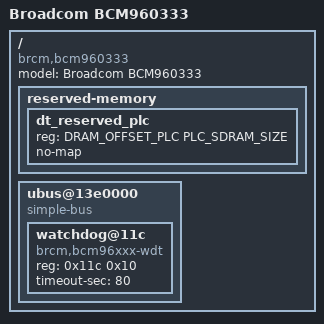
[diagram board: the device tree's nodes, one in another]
/*
 * Broadcom BCM63138 Reference Board DTS
 */

#include "bcm_963xx_template.dtsi"

/ {
    compatible = "brcm,bcm960333";
    model = "Broadcom BCM960333";

    reserved-memory {
        dt_reserved_plc {
          reg = <DRAM_OFFSET_PLC PLC_SDRAM_SIZE>;
          no-map;
        };
    };

    /* Legacy UBUS base */
    ubus@13e0000 {
    	compatible = "simple-bus";
    	ranges = <0 0x10000000 0x8000>;
    	#address-cells = <1>;
    	#size-cells = <1>;
    
    	watchdog@11c {
    		compatible = "brcm,bcm96xxx-wdt";
    		reg = <0x11c 0x10>;
    		timeout-sec = <80>;
    	};
    };
};
